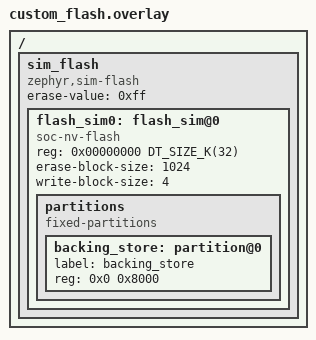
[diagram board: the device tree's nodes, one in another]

/ {

	sim_flash: sim_flash {
		compatible = "zephyr,sim-flash";

		erase-value = <0xff>;
		#size-cells = <1>;
		#address-cells = <1>;

		flash_sim0: flash_sim@0 {
			reg = <0x00000000 DT_SIZE_K(32)>;
			compatible = "soc-nv-flash";
			status = "okay";

			#size-cells = <1>;
			#address-cells = <1>;

			erase-block-size = <1024>;
			write-block-size = <4>;

			partitions {
				compatible = "fixed-partitions";
				#size-cells = <1>;
				#address-cells = <1>;

				backing_store: partition@0 {
					label = "backing_store";
					reg = <0x0 0x8000>;
				};
			};
		};
	};
};
